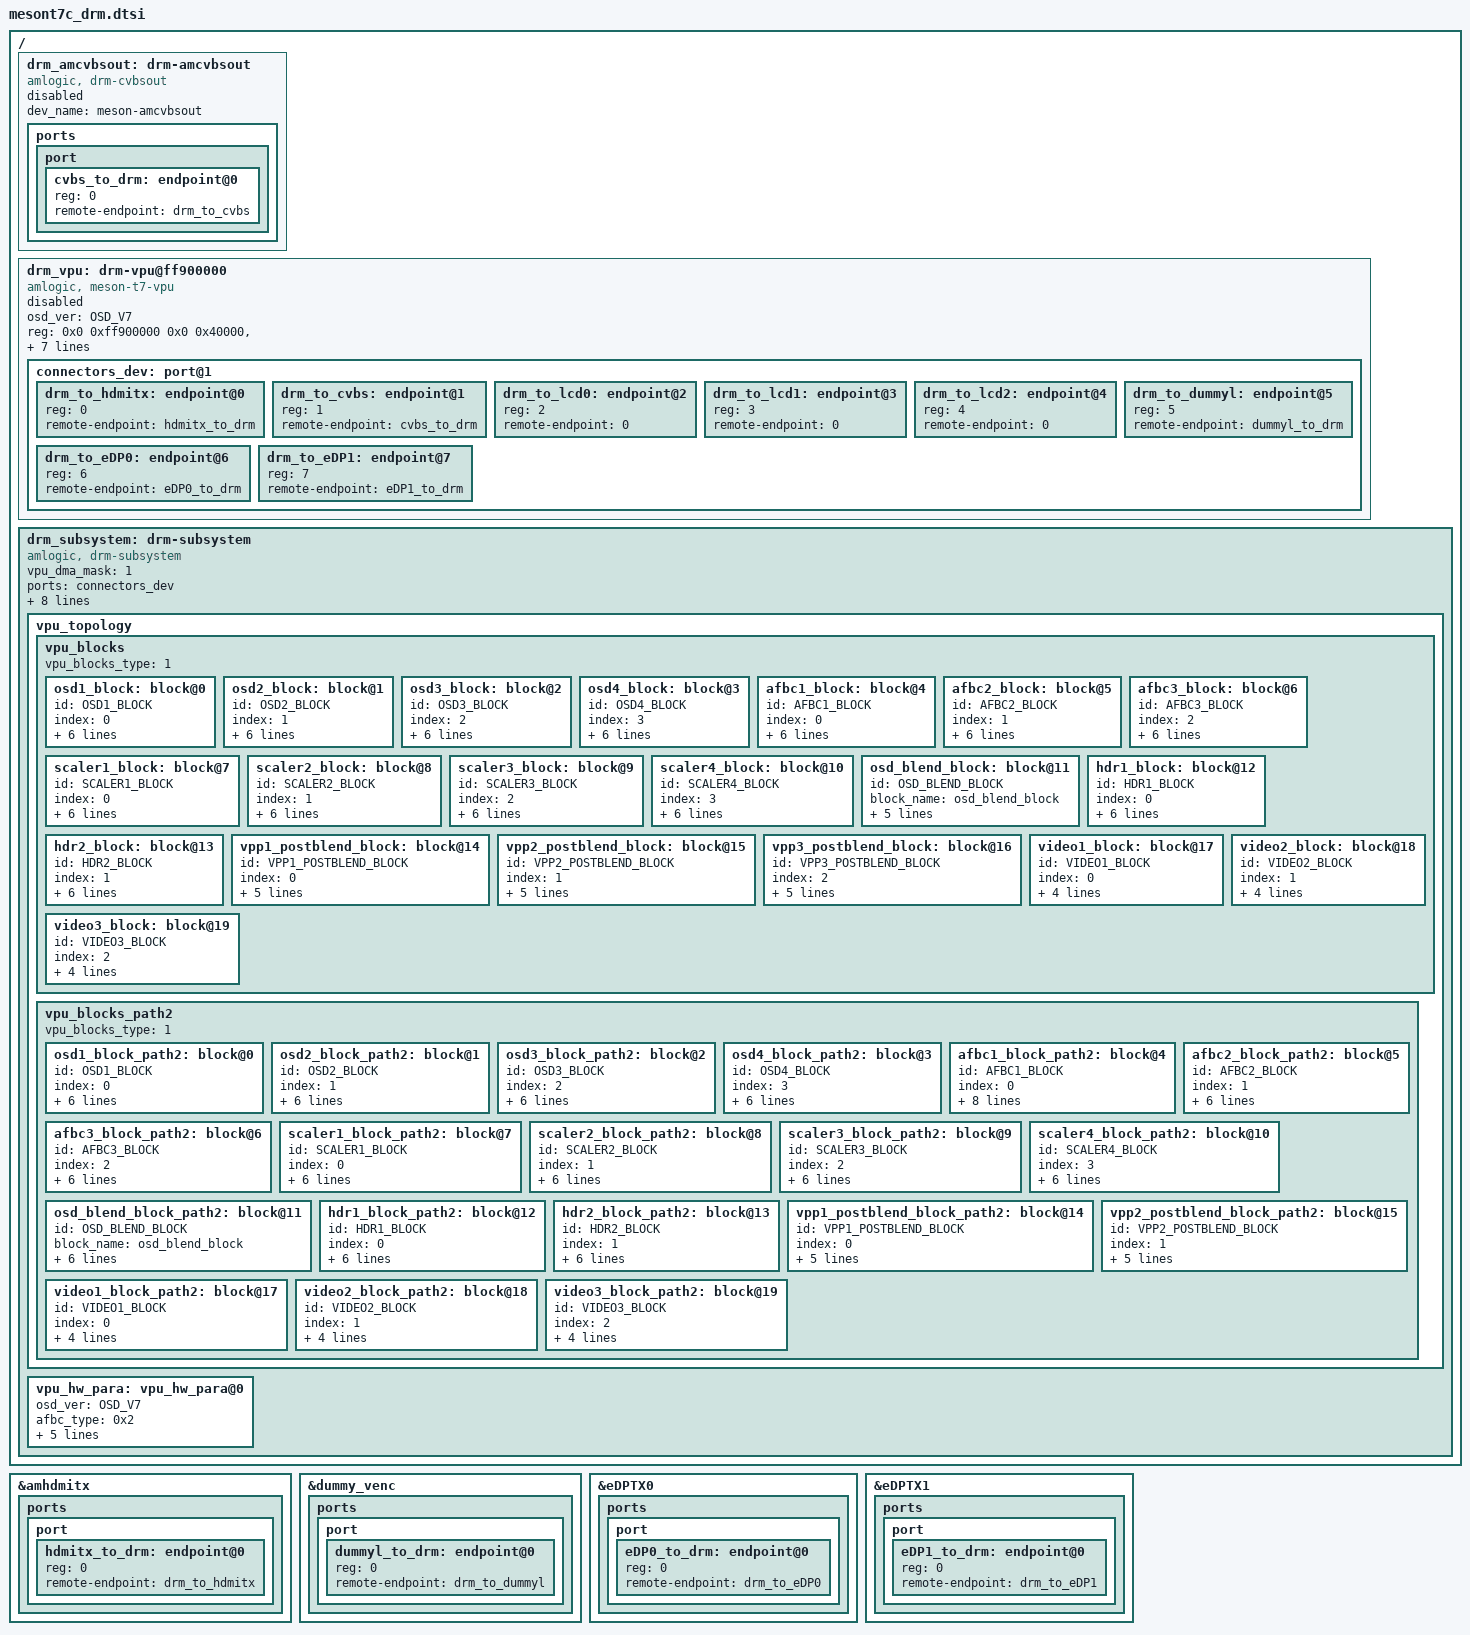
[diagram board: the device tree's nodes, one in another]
// SPDX-License-Identifier: (GPL-2.0+ OR MIT)
/*
 * Copyright (c) 2019 Amlogic, Inc. All rights reserved.
 */

#include <dt-bindings/display/meson-drm-ids.h>
#include "mesont7c.dtsi"

/ {
	drm_amcvbsout: drm-amcvbsout {
		status = "disabled";
		compatible = "amlogic, drm-cvbsout";
		dev_name = "meson-amcvbsout";
		ports {
			port {
				#address-cells = <1>;
				#size-cells = <0>;
				cvbs_to_drm: endpoint@0 {
					reg = <0>;
					remote-endpoint = <&drm_to_cvbs>;
				};
			};
		};
	};

	drm_vpu: drm-vpu@ff900000  {
		status = "disabled";
		compatible = "amlogic, meson-t7-vpu";
		osd_ver = /bits/ 8 <OSD_V7>;
		reg = <0x0 0xff900000 0x0 0x40000>,
			  <0x0 0xff63c000 0x0 0x2000>,
			  <0x0 0xff638000 0x0 0x2000>;
		reg-names = "base", "hhi", "dmc";
		interrupts = <GIC_SPI 197 IRQ_TYPE_EDGE_RISING>,
			<GIC_SPI 194 IRQ_TYPE_EDGE_RISING>,
			<GIC_SPI 82 IRQ_TYPE_EDGE_RISING>;
		interrupt-names = "drm-viu-vsync", "drm-viu2-vsync",
				"drm-viu3-vsync";
		clocks = <&clkc CLKID_VPU_CLKC_MUX>;
		clock-names = "vpu_clkc";
		dma-coherent;
		/*EXTERNAL port for driver outside of drm.*/
		connectors_dev: port@1 {
			#address-cells = <1>;
			#size-cells = <0>;
			drm_to_hdmitx: endpoint@0 {
				reg = <0>;
				remote-endpoint = <&hdmitx_to_drm>;
			};
			drm_to_cvbs: endpoint@1 {
				reg = <1>;
				remote-endpoint = <&cvbs_to_drm>;
			};
			drm_to_lcd0: endpoint@2 {
				reg = <2>;
				remote-endpoint = <0>;
			};
			drm_to_lcd1: endpoint@3 {
				reg = <3>;
				remote-endpoint = <0>;
			};
			drm_to_lcd2: endpoint@4 {
				reg = <4>;
				remote-endpoint = <0>;
			};
			drm_to_dummyl: endpoint@5 {
				reg = <5>;
				remote-endpoint = <&dummyl_to_drm>;
			};
			drm_to_eDP0: endpoint@6 {
				reg = <6>;
				remote-endpoint = <&eDP0_to_drm>;
			};
			drm_to_eDP1: endpoint@7 {
				reg = <7>;
				remote-endpoint = <&eDP1_to_drm>;
			};
		};
	};

	drm_subsystem: drm-subsystem {
		status = "okay";
		compatible = "amlogic, drm-subsystem";
		vpu_dma_mask = <1>; /* 0: <= 4G, 1: > 4G */
		ports = <&connectors_dev>;
		fbdev_sizes = <1920 1080 1920 2160 32>;
		osd_ver = /bits/ 8 <OSD_V7>;
		memory-region = <&logo_reserved>;
		crtc_masks = <7 7 1>; /*for encoder: 0:hdmi 1:lcd 2:cvbs*/
		crtcmask_of_osd = <0 0 1 2>; /* indicate the crtc mask of osd plane */
		crtcmask_of_video = <0 1 2>; /* indicate the crtc mask of video plane */
		vpu_block_select = <&vpu_blocks>;
		afbc_aligned_size = <1>; /*0:fbdev alloc non-afbc memory 1:fbdev alloc afbc memory*/

		vpu_topology: vpu_topology {
			/* 3 vpp output */
			vpu_blocks: vpu_blocks {
				/*0:scaler1 after osdblend, 1:scaler1 before osdblend*/
				vpu_blocks_type = <1>;
				osd1_block: block@0 {
					id = /bits/ 8 <OSD1_BLOCK>;
					index = /bits/ 8  <0>;
					type = /bits/ 8  <0>;
					block_name = "osd1_block";
					num_in_links = /bits/ 8  <0x0>;
					num_out_links = /bits/ 8  <0x1>;
					out_links = <0 &afbc1_block>;
					capability = /bits/ 64 <0x80000C9F>;
				};
				osd2_block: block@1 {
					id = /bits/ 8  <OSD2_BLOCK>;
					index = /bits/ 8  <1>;
					type = /bits/ 8  <0>;
					block_name = "osd2_block";
					num_in_links = /bits/ 8  <0x0>;
					num_out_links = /bits/ 8  <0x1>;
					out_links = <1 &afbc1_block>;
					capability = /bits/ 64 <0x80000C8F>;
				};
				osd3_block: block@2 {
					id = /bits/ 8  <OSD3_BLOCK>;
					index = /bits/ 8  <2>;
					type = /bits/ 8  <0>;
					block_name = "osd3_block";
					num_in_links = /bits/ 8  <0x0>;
					num_out_links = /bits/ 8  <0x1>;
					out_links = <0 &afbc2_block>;
					capability = /bits/ 64 <0x80000483>;
				};
				osd4_block: block@3 {
					id = /bits/ 8  <OSD4_BLOCK>;
					index = /bits/ 8  <3>;
					type = /bits/ 8  <0>;
					block_name = "osd4_block";
					num_in_links = /bits/ 8  <0x0>;
					num_out_links = /bits/ 8  <0x1>;
					out_links = <0 &afbc3_block>;
					capability = /bits/ 64 <0x800000083>;
				};
				afbc1_block: block@4 {
					id = /bits/ 8  <AFBC1_BLOCK>;
					index = /bits/ 8  <0>;
					type = /bits/ 8  <1>;
					block_name = "afbc1_block";
					num_in_links = /bits/ 8  <0x2>;
					in_links = <0 &osd1_block>,
						   <0 &osd2_block>;
					num_out_links = /bits/ 8  <0x2>;
					out_links = <0 &scaler1_block>,
						    <0 &scaler2_block>;
				};
				afbc2_block: block@5 {
					id = /bits/ 8  <AFBC2_BLOCK>;
					index = /bits/ 8  <1>;
					type = /bits/ 8  <1>;
					block_name = "afbc2_block";
					num_in_links = /bits/ 8  <0x1>;
					in_links = <0 &osd3_block>;
					num_out_links = /bits/ 8  <0x1>;
					out_links = <0 &scaler3_block>;
				};
				afbc3_block: block@6 {
					id = /bits/ 8  <AFBC3_BLOCK>;
					index = /bits/ 8  <2>;
					type = /bits/ 8  <1>;
					block_name = "afbc3_block";
					num_in_links = /bits/ 8  <0x1>;
					in_links = <0 &osd4_block>;
					num_out_links = /bits/ 8  <0x1>;
					out_links = <0 &scaler4_block>;
				};
				scaler1_block: block@7 {
					id = /bits/ 8  <SCALER1_BLOCK>;
					index = /bits/ 8  <0>;
					type = /bits/ 8  <2>;
					block_name = "scaler1_block";
					num_in_links = /bits/ 8  <0x1>;
					in_links = <0 &afbc1_block>;
					num_out_links = /bits/ 8  <0x1>;
					out_links = <0 &osd_blend_block>;
				};
				scaler2_block: block@8 {
					id = /bits/ 8  <SCALER2_BLOCK>;
					index = /bits/ 8  <1>;
					type = /bits/ 8  <2>;
					block_name = "scaler2_block";
					num_in_links = /bits/ 8  <0x1>;
					in_links = <1 &afbc1_block>;
					num_out_links = /bits/ 8  <0x1>;
					out_links = <1 &osd_blend_block>;
				};
				scaler3_block: block@9 {
					id = /bits/ 8  <SCALER3_BLOCK>;
					index = /bits/ 8  <2>;
					type = /bits/ 8  <2>;
					block_name = "scaler3_block";
					num_in_links = /bits/ 8  <0x1>;
					in_links = <0 &afbc2_block>;
					num_out_links = /bits/ 8  <0x1>;
					out_links = <0 &hdr2_block>;
				};
				scaler4_block: block@10 {
					id = /bits/ 8  <SCALER4_BLOCK>;
					index = /bits/ 8  <3>;
					type = /bits/ 8  <2>;
					block_name = "scaler4_block";
					num_in_links = /bits/ 8  <0x1>;
					in_links = <0 &afbc3_block>;
					num_out_links = /bits/ 8  <0x1>;
					out_links = <0 &vpp3_postblend_block>;
				};
				osd_blend_block: block@11 {
					id = /bits/ 8  <OSD_BLEND_BLOCK>;
					block_name = "osd_blend_block";
					type = /bits/ 8  <3>;
					num_in_links = /bits/ 8  <0x2>;
					in_links = <0 &scaler1_block>,
						<0 &scaler2_block>;
					num_out_links = /bits/ 8  <0x1>;
					out_links = <0 &hdr1_block>;
				};
				hdr1_block: block@12 {
					id = /bits/ 8  <HDR1_BLOCK>;
					index = /bits/ 8  <0>;
					block_name = "hdr1_block";
					type = /bits/ 8  <4>;
					num_in_links = /bits/ 8  <0x1>;
					in_links = <0 &osd_blend_block>;
					num_out_links = /bits/ 8  <0x1>;
					out_links = <0 &vpp1_postblend_block>;
				};
				hdr2_block: block@13 {
					id = /bits/ 8  <HDR2_BLOCK>;
					index = /bits/ 8  <1>;
					block_name = "hdr2_block";
					type = /bits/ 8  <4>;
					num_in_links = /bits/ 8  <0x1>;
					in_links = <0 &scaler3_block>;
					num_out_links = /bits/ 8  <0x1>;
					out_links = <0 &vpp2_postblend_block>;
				};
				vpp1_postblend_block: block@14 {
					id = /bits/ 8  <VPP1_POSTBLEND_BLOCK>;
					index = /bits/ 8  <0>;
					block_name = "vpp1_postblend_block";
					type = /bits/ 8  <6>;
					num_in_links = /bits/ 8  <0x1>;
					in_links = <0 &hdr1_block>;
					num_out_links = <0x0>;
				};
				vpp2_postblend_block: block@15 {
					id = /bits/ 8  <VPP2_POSTBLEND_BLOCK>;
					index = /bits/ 8  <1>;
					block_name = "vpp2_postblend_block";
					type = /bits/ 8  <6>;
					num_in_links = /bits/ 8  <0x1>;
					in_links = <1 &hdr2_block>;
					num_out_links = <0x0>;
				};
				vpp3_postblend_block: block@16 {
					id = /bits/ 8  <VPP3_POSTBLEND_BLOCK>;
					index = /bits/ 8  <2>;
					block_name = "vpp3_postblend_block";
					type = /bits/ 8  <6>;
					num_in_links = /bits/ 8  <0x1>;
					in_links = <0 &scaler4_block>;
					num_out_links = <0x0>;
				};
				video1_block: block@17 {
					id = /bits/ 8 <VIDEO1_BLOCK>;
					index = /bits/ 8  <0>;
					type = /bits/ 8  <7>;
					block_name = "video1_block";
					num_in_links = /bits/ 8  <0x0>;
					num_out_links = /bits/ 8  <0x0>;
				};
				video2_block: block@18 {
					id = /bits/ 8 <VIDEO2_BLOCK>;
					index = /bits/ 8  <1>;
					type = /bits/ 8  <7>;
					block_name = "video2_block";
					num_in_links = /bits/ 8  <0x0>;
					num_out_links = /bits/ 8  <0x0>;
				};
				video3_block: block@19 {
					id = /bits/ 8 <VIDEO3_BLOCK>;
					index = /bits/ 8  <2>;
					type = /bits/ 8  <7>;
					block_name = "video3_block";
					num_in_links = /bits/ 8  <0x0>;
					num_out_links = /bits/ 8  <0x0>;
				};
			};
			/* 2 vpp output */
			vpu_blocks_path2: vpu_blocks_path2 {
				/*0:scaler1 after osdblend, 1:scaler1 before osdblend*/
				vpu_blocks_type = <1>;
				osd1_block_path2: block@0 {
					id = /bits/ 8 <OSD1_BLOCK>;
					index = /bits/ 8  <0>;
					type = /bits/ 8  <0>;
					block_name = "osd1_block";
					num_in_links = /bits/ 8  <0x0>;
					num_out_links = /bits/ 8  <0x1>;
					out_links = <0 &afbc1_block_path2>;
					capability = /bits/ 64 <0x80000C9F>;
				};
				osd2_block_path2: block@1 {
					id = /bits/ 8  <OSD2_BLOCK>;
					index = /bits/ 8  <1>;
					type = /bits/ 8  <0>;
					block_name = "osd2_block";
					num_in_links = /bits/ 8  <0x0>;
					num_out_links = /bits/ 8  <0x1>;
					out_links = <1 &afbc1_block_path2>;
					capability = /bits/ 64 <0x80000C8F>;
				};
				osd3_block_path2: block@2 {
					id = /bits/ 8  <OSD3_BLOCK>;
					index = /bits/ 8  <2>;
					type = /bits/ 8  <0>;
					block_name = "osd3_block";
					num_in_links = /bits/ 8  <0x0>;
					num_out_links = /bits/ 8  <0x1>;
					out_links = <0 &afbc2_block_path2>;
					capability = /bits/ 64 <0x80000483>;
				};
				osd4_block_path2: block@3 {
					id = /bits/ 8  <OSD4_BLOCK>;
					index = /bits/ 8  <3>;
					type = /bits/ 8  <0>;
					block_name = "osd4_block";
					num_in_links = /bits/ 8  <0x0>;
					num_out_links = /bits/ 8  <0x1>;
					out_links = <0 &afbc3_block_path2>;
					capability = /bits/ 64 <0x800000C8F>;
				};
				afbc1_block_path2: block@4 {
					id = /bits/ 8  <AFBC1_BLOCK>;
					index = /bits/ 8  <0>;
					type = /bits/ 8  <1>;
					block_name = "afbc1_block";
					num_in_links = /bits/ 8  <0x2>;
					in_links = <0 &osd1_block_path2>,
						   <0 &osd2_block_path2>;
					num_out_links = /bits/ 8  <0x2>;
					out_links = <0 &scaler1_block_path2>,
						    <0 &scaler2_block_path2>;
				};
				afbc2_block_path2: block@5 {
					id = /bits/ 8  <AFBC2_BLOCK>;
					index = /bits/ 8  <1>;
					type = /bits/ 8  <1>;
					block_name = "afbc2_block";
					num_in_links = /bits/ 8  <0x1>;
					in_links = <0 &osd3_block_path2>;
					num_out_links = /bits/ 8  <0x1>;
					out_links = <0 &scaler3_block_path2>;
				};
				afbc3_block_path2: block@6 {
					id = /bits/ 8  <AFBC3_BLOCK>;
					index = /bits/ 8  <2>;
					type = /bits/ 8  <1>;
					block_name = "afbc3_block";
					num_in_links = /bits/ 8  <0x1>;
					in_links = <0 &osd4_block_path2>;
					num_out_links = /bits/ 8  <0x1>;
					out_links = <0 &scaler4_block_path2>;
				};
				scaler1_block_path2: block@7 {
					id = /bits/ 8  <SCALER1_BLOCK>;
					index = /bits/ 8  <0>;
					type = /bits/ 8  <2>;
					block_name = "scaler1_block";
					num_in_links = /bits/ 8  <0x1>;
					in_links = <0 &afbc1_block_path2>;
					num_out_links = /bits/ 8  <0x1>;
					out_links = <0 &osd_blend_block_path2>;
				};
				scaler2_block_path2: block@8 {
					id = /bits/ 8  <SCALER2_BLOCK>;
					index = /bits/ 8  <1>;
					type = /bits/ 8  <2>;
					block_name = "scaler2_block";
					num_in_links = /bits/ 8  <0x1>;
					in_links = <1 &afbc1_block_path2>;
					num_out_links = /bits/ 8  <0x1>;
					out_links = <1 &osd_blend_block_path2>;
				};
				scaler3_block_path2: block@9 {
					id = /bits/ 8  <SCALER3_BLOCK>;
					index = /bits/ 8  <2>;
					type = /bits/ 8  <2>;
					block_name = "scaler3_block";
					num_in_links = /bits/ 8  <0x1>;
					in_links = <0 &afbc2_block_path2>;
					num_out_links = /bits/ 8  <0x1>;
					out_links = <0 &hdr2_block_path2>;
				};
				scaler4_block_path2: block@10 {
					id = /bits/ 8  <SCALER4_BLOCK>;
					index = /bits/ 8  <3>;
					type = /bits/ 8  <2>;
					block_name = "scaler4_block";
					num_in_links = /bits/ 8  <0x1>;
					in_links = <0 &afbc3_block_path2>;
					num_out_links = /bits/ 8  <0x1>;
					out_links = <2 &osd_blend_block_path2>;
				};
				osd_blend_block_path2: block@11 {
					id = /bits/ 8  <OSD_BLEND_BLOCK>;
					block_name = "osd_blend_block";
					type = /bits/ 8  <3>;
					num_in_links = /bits/ 8  <0x2>;
					in_links = <0 &scaler1_block_path2>,
						<0 &scaler2_block_path2>,
						<0 &scaler4_block_path2>;
					num_out_links = /bits/ 8  <0x1>;
					out_links = <0 &hdr1_block_path2>;
				};
				hdr1_block_path2: block@12 {
					id = /bits/ 8  <HDR1_BLOCK>;
					index = /bits/ 8  <0>;
					block_name = "hdr1_block";
					type = /bits/ 8  <4>;
					num_in_links = /bits/ 8  <0x1>;
					in_links = <0 &osd_blend_block_path2>;
					num_out_links = /bits/ 8  <0x1>;
					out_links = <0 &vpp1_postblend_block_path2>;
				};
				hdr2_block_path2: block@13 {
					id = /bits/ 8  <HDR2_BLOCK>;
					index = /bits/ 8  <1>;
					block_name = "hdr2_block";
					type = /bits/ 8  <4>;
					num_in_links = /bits/ 8  <0x1>;
					in_links = <0 &scaler3_block_path2>;
					num_out_links = /bits/ 8  <0x1>;
					out_links = <0 &vpp2_postblend_block_path2>;
				};
				vpp1_postblend_block_path2: block@14 {
					id = /bits/ 8  <VPP1_POSTBLEND_BLOCK>;
					index = /bits/ 8  <0>;
					block_name = "vpp1_postblend_block";
					type = /bits/ 8  <6>;
					num_in_links = /bits/ 8  <0x1>;
					in_links = <0 &hdr1_block_path2>;
					num_out_links = <0x0>;
				};
				vpp2_postblend_block_path2: block@15 {
					id = /bits/ 8  <VPP2_POSTBLEND_BLOCK>;
					index = /bits/ 8  <1>;
					block_name = "vpp2_postblend_block";
					type = /bits/ 8  <6>;
					num_in_links = /bits/ 8  <0x1>;
					in_links = <1 &hdr2_block_path2>;
					num_out_links = <0x0>;
				};
				video1_block_path2: block@17 {
					id = /bits/ 8 <VIDEO1_BLOCK>;
					index = /bits/ 8  <0>;
					type = /bits/ 8  <7>;
					block_name = "video1_block";
					num_in_links = /bits/ 8  <0x0>;
					num_out_links = /bits/ 8  <0x0>;
				};
				video2_block_path2: block@18 {
					id = /bits/ 8 <VIDEO2_BLOCK>;
					index = /bits/ 8  <1>;
					type = /bits/ 8  <7>;
					block_name = "video2_block";
					num_in_links = /bits/ 8  <0x0>;
					num_out_links = /bits/ 8  <0x0>;
				};
				video3_block_path2: block@19 {
					id = /bits/ 8 <VIDEO3_BLOCK>;
					index = /bits/ 8  <2>;
					type = /bits/ 8  <7>;
					block_name = "video3_block";
					num_in_links = /bits/ 8  <0x0>;
					num_out_links = /bits/ 8  <0x0>;
				};
			};
		};

		vpu_hw_para: vpu_hw_para@0 {
			osd_ver = /bits/ 8 <OSD_V7>;
			afbc_type = /bits/ 8 <0x2>;
			has_deband = /bits/ 8 <0x1>;
			has_lut = /bits/ 8 <0x1>;
			has_rdma = /bits/ 8 <0x1>;
			osd_fifo_len = /bits/ 8 <64>;
			vpp_fifo_len = /bits/ 32 <0xfff>;
		};
	};
};

&amhdmitx {
	ports {
		port {
			#address-cells = <1>;
			#size-cells = <0>;
			hdmitx_to_drm: endpoint@0 {
				reg = <0>;
				remote-endpoint = <&drm_to_hdmitx>;
			};
		};
	};
};

&dummy_venc {
	ports {
		port {
			#address-cells = <1>;
			#size-cells = <0>;
			dummyl_to_drm: endpoint@0 {
				reg = <0>;
				remote-endpoint = <&drm_to_dummyl>;
			};
		};
	};
};

&eDPTX0 {
	ports {
		port {
			#address-cells = <1>;
			#size-cells = <0>;
			eDP0_to_drm: endpoint@0 {
				reg = <0>;
				remote-endpoint = <&drm_to_eDP0>;
			};
		};
	};
};

&eDPTX1 {
	ports {
		port {
			#address-cells = <1>;
			#size-cells = <0>;
			eDP1_to_drm: endpoint@0 {
				reg = <0>;
				remote-endpoint = <&drm_to_eDP1>;
			};
		};
	};
};
